/* CHECKSUM={C93B91C7D6862505D2C18CCA284AF854CCAFAA53} */
/* Daimler Truck AG */
/* All rights reserved */
/* Description: LIN Description file */
/* Network: THERMO_LIN2 */
/* Release: 2026-7a */
/* Engineer: Bianda, TP/XMS; W. Griebel EVOUL */
/* Creation Date: 2026-02-12 */
/* Status: RELEASED */
/* XDIS-Database: CVD-Database */

LIN_description_file;
LIN_protocol_version = "2.1";
LIN_language_version = "2.1";
LIN_speed = 19.200 kbps;

Channel_name = "THERMO_LIN2";

Nodes {
  Master : TIO_LIN2_Master, 5.000 ms, 0.200 ms;
  Slaves : CABP2, CPH2, ERC2, EXV2, FRVC10, FRVC19, FRVC2, FRVC21, FRVC25, FRVC26, FRVC3, FRVC4, P_T_SENSOR;
}

Signals {
  ASC_TIO_ERC2 : 2, 3, TIO_LIN2_Master, ERC2;
  ActPosnSave_Rq_TIO_FRVC10 : 1, 0, TIO_LIN2_Master, FRVC10;
  ActPosnSave_Rq_TIO_FRVC19 : 1, 0, TIO_LIN2_Master, FRVC19;
  ActPosnSave_Rq_TIO_FRVC2 : 1, 0, TIO_LIN2_Master, FRVC2;
  ActPosnSave_Rq_TIO_FRVC21 : 1, 0, TIO_LIN2_Master, FRVC21;
  ActPosnSave_Rq_TIO_FRVC25 : 1, 0, TIO_LIN2_Master, FRVC25;
  ActPosnSave_Rq_TIO_FRVC26 : 1, 0, TIO_LIN2_Master, FRVC26;
  ActPosnSave_Rq_TIO_FRVC3 : 1, 0, TIO_LIN2_Master, FRVC3;
  ActPosnSave_Rq_TIO_FRVC4 : 1, 0, TIO_LIN2_Master, FRVC4;
  ActlCurr_Cval_CABP2 : 8, 255, CABP2, TIO_LIN2_Master;
  AllPosnAdj_Stat_FRVC10 : 1, 0, FRVC10, TIO_LIN2_Master;
  AllPosnAdj_Stat_FRVC19 : 1, 0, FRVC19, TIO_LIN2_Master;
  AllPosnAdj_Stat_FRVC2 : 1, 0, FRVC2, TIO_LIN2_Master;
  AllPosnAdj_Stat_FRVC21 : 1, 0, FRVC21, TIO_LIN2_Master;
  AllPosnAdj_Stat_FRVC25 : 1, 0, FRVC25, TIO_LIN2_Master;
  AllPosnAdj_Stat_FRVC26 : 1, 0, FRVC26, TIO_LIN2_Master;
  AllPosnAdj_Stat_FRVC3 : 1, 0, FRVC3, TIO_LIN2_Master;
  AllPosnAdj_Stat_FRVC4 : 1, 0, FRVC4, TIO_LIN2_Master;
  BlockFlt_Stat_CABP2 : 2, 3, CABP2, TIO_LIN2_Master;
  CmprOn_Rq_TIO_ERC2 : 2, 3, TIO_LIN2_Master, ERC2;
  CmprOprtnV2_Stat_ERC2 : 3, 7, ERC2, TIO_LIN2_Master;
  CmprSpdTrgtV2_Rq_TIO_ERC2 : 8, 255, TIO_LIN2_Master, ERC2;
  CmprSpdV2_Cval_ERC2 : 8, 255, ERC2, TIO_LIN2_Master;
  ComFlt_ERC2 : 1, 0, ERC2, TIO_LIN2_Master;
  CoolntInTemp_Cval_CPH_BATT1 : 8, 255, CPH2, TIO_LIN2_Master;
  CoolntOutTemp_Cval_CPH_BATT1 : 8, 255, CPH2, TIO_LIN2_Master;
  CoolntPreHt_Stat_CPH_BATT1 : 4, 15, CPH2, TIO_LIN2_Master;
  CoolntTemp_Rq_TIO_CPH_BATT1 : 8, 255, TIO_LIN2_Master, CPH2;
  CptProtn_Stat_CPH_BATT1 : 2, 3, CPH2, TIO_LIN2_Master;
  Crash_Lin : 2, 3, TIO_LIN2_Master, ERC2;
  CurrLimFlt_ERC2 : 1, 0, ERC2, TIO_LIN2_Master;
  DCDCCnvrFai_Stat_CPH_BATT1 : 2, 3, CPH2, TIO_LIN2_Master;
  DIAG_Stat_Aliv_St_Cnt_ERC2 : 4, 0, ERC2, TIO_LIN2_Master;
  DIAG_Stat_Data1_ERC2 : 6, 0, ERC2, TIO_LIN2_Master;
  DIAG_Stat_Data2_ERC2 : 6, 0, ERC2, TIO_LIN2_Master;
  DIAG_Stat_Data3_ERC2 : 6, 0, ERC2, TIO_LIN2_Master;
  DIAG_Stat_Data4_ERC2 : 6, 0, ERC2, TIO_LIN2_Master;
  DIAG_Stat_Data5_ERC2 : 6, 0, ERC2, TIO_LIN2_Master;
  DIAG_Stat_Data6_ERC2 : 6, 0, ERC2, TIO_LIN2_Master;
  DIAG_Stat_Data7_ERC2 : 6, 0, ERC2, TIO_LIN2_Master;
  DIAG_Stat_Data8_ERC2 : 6, 0, ERC2, TIO_LIN2_Master;
  DIAG_Stat_Idx_Actl_ERC2 : 6, 0, ERC2, TIO_LIN2_Master;
  DIAG_Stat_Num_Max_ERC2 : 6, 0, ERC2, TIO_LIN2_Master;
  Dischrg_Rq_TIO_CPH_BATT1 : 1, 0, TIO_LIN2_Master, CPH2;
  Dischrg_Stat_CPH_BATT1 : 4, 15, CPH2, TIO_LIN2_Master;
  DryRun_Flt_Stat_CABP2 : 2, 3, CABP2, TIO_LIN2_Master;
  EXV2_Fault_Stat : 4, 15, EXV2, TIO_LIN2_Master;
  EXV2_OverTemp_Warn : 2, 3, EXV2, TIO_LIN2_Master;
  EXV2_Pos : 10, 1023, EXV2, TIO_LIN2_Master;
  EXV2_Run_Stat : 2, 3, EXV2, TIO_LIN2_Master;
  EXV2_SpdMd : 3, 7, EXV2, TIO_LIN2_Master;
  EXV2_Stall_Dtct_Stat : 2, 3, EXV2, TIO_LIN2_Master;
  EXV2_Version : 3, 7, EXV2, TIO_LIN2_Master;
  EXV2_Volt_Stat : 2, 3, EXV2, TIO_LIN2_Master;
  EXV2_curInit_Stat : 2, 3, EXV2, TIO_LIN2_Master;
  ElctrcFlt_Stat_CABP2 : 2, 3, CABP2, TIO_LIN2_Master;
  ElctrcTemp_Cval_CABP2 : 8, 255, CABP2, TIO_LIN2_Master;
  EltlErr_Stat_FRVC10 : 1, 0, FRVC10, TIO_LIN2_Master;
  EltlErr_Stat_FRVC19 : 1, 0, FRVC19, TIO_LIN2_Master;
  EltlErr_Stat_FRVC2 : 1, 0, FRVC2, TIO_LIN2_Master;
  EltlErr_Stat_FRVC21 : 1, 0, FRVC21, TIO_LIN2_Master;
  EltlErr_Stat_FRVC25 : 1, 0, FRVC25, TIO_LIN2_Master;
  EltlErr_Stat_FRVC26 : 1, 0, FRVC26, TIO_LIN2_Master;
  EltlErr_Stat_FRVC3 : 1, 0, FRVC3, TIO_LIN2_Master;
  EltlErr_Stat_FRVC4 : 1, 0, FRVC4, TIO_LIN2_Master;
  Err_Stat_FRVC10 : 4, 15, FRVC10, TIO_LIN2_Master;
  Err_Stat_FRVC19 : 4, 15, FRVC19, TIO_LIN2_Master;
  Err_Stat_FRVC2 : 4, 15, FRVC2, TIO_LIN2_Master;
  Err_Stat_FRVC21 : 4, 15, FRVC21, TIO_LIN2_Master;
  Err_Stat_FRVC25 : 4, 15, FRVC25, TIO_LIN2_Master;
  Err_Stat_FRVC26 : 4, 15, FRVC26, TIO_LIN2_Master;
  Err_Stat_FRVC3 : 4, 15, FRVC3, TIO_LIN2_Master;
  Err_Stat_FRVC4 : 4, 15, FRVC4, TIO_LIN2_Master;
  ExtPowerSupFlt_ERC2 : 1, 0, ERC2, TIO_LIN2_Master;
  GrpErr_Stat_FRVC10 : 1, 0, FRVC10, TIO_LIN2_Master;
  GrpErr_Stat_FRVC19 : 1, 0, FRVC19, TIO_LIN2_Master;
  GrpErr_Stat_FRVC2 : 1, 0, FRVC2, TIO_LIN2_Master;
  GrpErr_Stat_FRVC21 : 1, 0, FRVC21, TIO_LIN2_Master;
  GrpErr_Stat_FRVC25 : 1, 0, FRVC25, TIO_LIN2_Master;
  GrpErr_Stat_FRVC26 : 1, 0, FRVC26, TIO_LIN2_Master;
  GrpErr_Stat_FRVC3 : 1, 0, FRVC3, TIO_LIN2_Master;
  GrpErr_Stat_FRVC4 : 1, 0, FRVC4, TIO_LIN2_Master;
  HVAC_EXV2_Init_Dir : 2, 3, TIO_LIN2_Master, EXV2;
  HVAC_EXV2_Init_Rq : 3, 7, TIO_LIN2_Master, EXV2;
  HVAC_EXV2_Move_Enbl : 2, 3, TIO_LIN2_Master, EXV2;
  HVAC_EXV2_Set_Rq : 10, 1023, TIO_LIN2_Master, EXV2;
  HVAC_EXV2_SpdMd_Rq : 3, 7, TIO_LIN2_Master, EXV2;
  HVAC_EXV2_Stall_Dtct_Enbl : 2, 3, TIO_LIN2_Master, EXV2;
  HVAC_EXV2_Trq_Md_Rq : 3, 7, TIO_LIN2_Master, EXV2;
  HVCurr_Cval_CPH_BATT1 : 8, 255, CPH2, TIO_LIN2_Master;
  HVOutOfRngWarn_Stat_CPH_BATT1 : 2, 3, CPH2, TIO_LIN2_Master;
  HVVolt_Cval_CPH_BATT1 : 16, 65535, CPH2, TIO_LIN2_Master;
  HV_DCCurr_Cval_ERC2 : 8, 255, ERC2, TIO_LIN2_Master;
  HV_PhaseCurr_Cval_ERC2 : 7, 127, ERC2, TIO_LIN2_Master;
  HV_VoltLimFlt_ERC2 : 1, 0, ERC2, TIO_LIN2_Master;
  HV_Volt_Cval_ERC2 : 8, 255, ERC2, TIO_LIN2_Master;
  HiCurrFai_Stat_CPH_BATT1 : 2, 3, CPH2, TIO_LIN2_Master;
  HotSptFai_Stat_CPH_BATT1 : 2, 3, CPH2, TIO_LIN2_Master;
  HtEnbl_Rq_TIO_CPH_BATT1 : 1, 0, TIO_LIN2_Master, CPH2;
  IGBTDrvFai_Stat_CPH_BATT1 : 2, 3, CPH2, TIO_LIN2_Master;
  InfVarPosn_Cval_FRVC10 : 16, 65535, FRVC10, TIO_LIN2_Master;
  InfVarPosn_Cval_FRVC19 : 16, 65535, FRVC19, TIO_LIN2_Master;
  InfVarPosn_Cval_FRVC2 : 16, 65535, FRVC2, TIO_LIN2_Master;
  InfVarPosn_Cval_FRVC21 : 16, 65535, FRVC21, TIO_LIN2_Master;
  InfVarPosn_Cval_FRVC25 : 16, 65535, FRVC25, TIO_LIN2_Master;
  InfVarPosn_Cval_FRVC26 : 16, 65535, FRVC26, TIO_LIN2_Master;
  InfVarPosn_Cval_FRVC3 : 16, 65535, FRVC3, TIO_LIN2_Master;
  InfVarPosn_Cval_FRVC4 : 16, 65535, FRVC4, TIO_LIN2_Master;
  InfVarPosn_Rq_TIO_FRVC10 : 16, 65535, TIO_LIN2_Master, FRVC10;
  InfVarPosn_Rq_TIO_FRVC19 : 16, 65535, TIO_LIN2_Master, FRVC19;
  InfVarPosn_Rq_TIO_FRVC2 : 16, 65535, TIO_LIN2_Master, FRVC2;
  InfVarPosn_Rq_TIO_FRVC21 : 16, 65535, TIO_LIN2_Master, FRVC21;
  InfVarPosn_Rq_TIO_FRVC25 : 16, 65535, TIO_LIN2_Master, FRVC25;
  InfVarPosn_Rq_TIO_FRVC26 : 16, 65535, TIO_LIN2_Master, FRVC26;
  InfVarPosn_Rq_TIO_FRVC3 : 16, 65535, TIO_LIN2_Master, FRVC3;
  InfVarPosn_Rq_TIO_FRVC4 : 16, 65535, TIO_LIN2_Master, FRVC4;
  IntFai_Stat_CPH_BATT1 : 2, 3, CPH2, TIO_LIN2_Master;
  IntPowerSupFlt_ERC2 : 1, 0, ERC2, TIO_LIN2_Master;
  InvTemp_Cval_ERC2 : 8, 255, ERC2, TIO_LIN2_Master;
  LVOutOfRngWarn_Stat_CPH_BATT1 : 2, 3, CPH2, TIO_LIN2_Master;
  LoVolt_Cval_CABP2 : 8, 255, CABP2, TIO_LIN2_Master;
  MechBreakErr_Stat_FRVC10 : 1, 0, FRVC10, TIO_LIN2_Master;
  MechBreakErr_Stat_FRVC19 : 1, 0, FRVC19, TIO_LIN2_Master;
  MechBreakErr_Stat_FRVC2 : 1, 0, FRVC2, TIO_LIN2_Master;
  MechBreakErr_Stat_FRVC21 : 1, 0, FRVC21, TIO_LIN2_Master;
  MechBreakErr_Stat_FRVC25 : 1, 0, FRVC25, TIO_LIN2_Master;
  MechBreakErr_Stat_FRVC26 : 1, 0, FRVC26, TIO_LIN2_Master;
  MechBreakErr_Stat_FRVC3 : 1, 0, FRVC3, TIO_LIN2_Master;
  MechBreakErr_Stat_FRVC4 : 1, 0, FRVC4, TIO_LIN2_Master;
  Mon_Stat_CABP2 : 2, 3, CABP2, TIO_LIN2_Master;
  Move_Stat_FRVC10 : 4, 15, FRVC10, TIO_LIN2_Master;
  Move_Stat_FRVC19 : 4, 15, FRVC19, TIO_LIN2_Master;
  Move_Stat_FRVC2 : 4, 15, FRVC2, TIO_LIN2_Master;
  Move_Stat_FRVC21 : 4, 15, FRVC21, TIO_LIN2_Master;
  Move_Stat_FRVC25 : 4, 15, FRVC25, TIO_LIN2_Master;
  Move_Stat_FRVC26 : 4, 15, FRVC26, TIO_LIN2_Master;
  Move_Stat_FRVC3 : 4, 15, FRVC3, TIO_LIN2_Master;
  Move_Stat_FRVC4 : 4, 15, FRVC4, TIO_LIN2_Master;
  OverCurrFlt_Stat_CABP2 : 2, 3, CABP2, TIO_LIN2_Master;
  OverHeatWarn_Stat_CPH_BATT1 : 2, 3, CPH2, TIO_LIN2_Master;
  OverTempErr_Stat_FRVC10 : 1, 0, FRVC10, TIO_LIN2_Master;
  OverTempErr_Stat_FRVC19 : 1, 0, FRVC19, TIO_LIN2_Master;
  OverTempErr_Stat_FRVC2 : 1, 0, FRVC2, TIO_LIN2_Master;
  OverTempErr_Stat_FRVC21 : 1, 0, FRVC21, TIO_LIN2_Master;
  OverTempErr_Stat_FRVC25 : 1, 0, FRVC25, TIO_LIN2_Master;
  OverTempErr_Stat_FRVC26 : 1, 0, FRVC26, TIO_LIN2_Master;
  OverTempErr_Stat_FRVC3 : 1, 0, FRVC3, TIO_LIN2_Master;
  OverTempErr_Stat_FRVC4 : 1, 0, FRVC4, TIO_LIN2_Master;
  OverTempFlt_Stat_CABP2 : 2, 3, CABP2, TIO_LIN2_Master;
  OverTempWarn_Stat_FRVC10 : 1, 0, FRVC10, TIO_LIN2_Master;
  OverTempWarn_Stat_FRVC19 : 1, 0, FRVC19, TIO_LIN2_Master;
  OverTempWarn_Stat_FRVC2 : 1, 0, FRVC2, TIO_LIN2_Master;
  OverTempWarn_Stat_FRVC21 : 1, 0, FRVC21, TIO_LIN2_Master;
  OverTempWarn_Stat_FRVC25 : 1, 0, FRVC25, TIO_LIN2_Master;
  OverTempWarn_Stat_FRVC26 : 1, 0, FRVC26, TIO_LIN2_Master;
  OverTempWarn_Stat_FRVC3 : 1, 0, FRVC3, TIO_LIN2_Master;
  OverTempWarn_Stat_FRVC4 : 1, 0, FRVC4, TIO_LIN2_Master;
  OverVoltErr_Stat_FRVC10 : 1, 0, FRVC10, TIO_LIN2_Master;
  OverVoltErr_Stat_FRVC19 : 1, 0, FRVC19, TIO_LIN2_Master;
  OverVoltErr_Stat_FRVC2 : 1, 0, FRVC2, TIO_LIN2_Master;
  OverVoltErr_Stat_FRVC21 : 1, 0, FRVC21, TIO_LIN2_Master;
  OverVoltErr_Stat_FRVC25 : 1, 0, FRVC25, TIO_LIN2_Master;
  OverVoltErr_Stat_FRVC26 : 1, 0, FRVC26, TIO_LIN2_Master;
  OverVoltErr_Stat_FRVC3 : 1, 0, FRVC3, TIO_LIN2_Master;
  OverVoltErr_Stat_FRVC4 : 1, 0, FRVC4, TIO_LIN2_Master;
  PWM_Stat_CABP2 : 2, 3, CABP2, TIO_LIN2_Master;
  P_T_Sens2_ChkSum_Err : 1, 0, P_T_SENSOR, TIO_LIN2_Master;
  P_T_Sens2_CoolPress : 12, 4095, P_T_SENSOR, TIO_LIN2_Master;
  P_T_Sens2_CoolTemp : 12, 4095, P_T_SENSOR, TIO_LIN2_Master;
  P_T_Sens2_FailTest_Compl : 1, 0, P_T_SENSOR, TIO_LIN2_Master;
  P_T_Sens2_Global_Err : 1, 0, P_T_SENSOR, TIO_LIN2_Master;
  P_T_Sens2_IntTemp : 12, 4095, P_T_SENSOR, TIO_LIN2_Master;
  PerctSpd_Cval_CABP2 : 8, 255, CABP2, TIO_LIN2_Master;
  Perct_Cval_CPH_BATT1 : 8, 255, CPH2, TIO_LIN2_Master;
  Perct_Rq_TIO_CPH_BATT1 : 8, 255, TIO_LIN2_Master, CPH2;
  PosSnaErr_Stat_FRVC10 : 1, 0, FRVC10, TIO_LIN2_Master;
  PosSnaErr_Stat_FRVC19 : 1, 0, FRVC19, TIO_LIN2_Master;
  PosSnaErr_Stat_FRVC2 : 1, 0, FRVC2, TIO_LIN2_Master;
  PosSnaErr_Stat_FRVC21 : 1, 0, FRVC21, TIO_LIN2_Master;
  PosSnaErr_Stat_FRVC25 : 1, 0, FRVC25, TIO_LIN2_Master;
  PosSnaErr_Stat_FRVC26 : 1, 0, FRVC26, TIO_LIN2_Master;
  PosSnaErr_Stat_FRVC3 : 1, 0, FRVC3, TIO_LIN2_Master;
  PosSnaErr_Stat_FRVC4 : 1, 0, FRVC4, TIO_LIN2_Master;
  PostRunMode_CABP2 : 3, 0, CABP2, TIO_LIN2_Master;
  PowerCons_Cval_ERC2 : 8, 255, ERC2, TIO_LIN2_Master;
  RefRunEnbl_Rq_TIO_FRVC10 : 2, 3, TIO_LIN2_Master, FRVC10;
  RefRunEnbl_Rq_TIO_FRVC19 : 2, 3, TIO_LIN2_Master, FRVC19;
  RefRunEnbl_Rq_TIO_FRVC2 : 2, 3, TIO_LIN2_Master, FRVC2;
  RefRunEnbl_Rq_TIO_FRVC21 : 2, 3, TIO_LIN2_Master, FRVC21;
  RefRunEnbl_Rq_TIO_FRVC25 : 2, 3, TIO_LIN2_Master, FRVC25;
  RefRunEnbl_Rq_TIO_FRVC26 : 2, 3, TIO_LIN2_Master, FRVC26;
  RefRunEnbl_Rq_TIO_FRVC3 : 2, 3, TIO_LIN2_Master, FRVC3;
  RefRunEnbl_Rq_TIO_FRVC4 : 2, 3, TIO_LIN2_Master, FRVC4;
  RefRunErr_Stat_FRVC10 : 1, 0, FRVC10, TIO_LIN2_Master;
  RefRunErr_Stat_FRVC19 : 1, 0, FRVC19, TIO_LIN2_Master;
  RefRunErr_Stat_FRVC2 : 1, 0, FRVC2, TIO_LIN2_Master;
  RefRunErr_Stat_FRVC21 : 1, 0, FRVC21, TIO_LIN2_Master;
  RefRunErr_Stat_FRVC25 : 1, 0, FRVC25, TIO_LIN2_Master;
  RefRunErr_Stat_FRVC26 : 1, 0, FRVC26, TIO_LIN2_Master;
  RefRunErr_Stat_FRVC3 : 1, 0, FRVC3, TIO_LIN2_Master;
  RefRunErr_Stat_FRVC4 : 1, 0, FRVC4, TIO_LIN2_Master;
  RefRun_Stat_FRVC10 : 1, 0, FRVC10, TIO_LIN2_Master;
  RefRun_Stat_FRVC19 : 1, 0, FRVC19, TIO_LIN2_Master;
  RefRun_Stat_FRVC2 : 1, 0, FRVC2, TIO_LIN2_Master;
  RefRun_Stat_FRVC21 : 1, 0, FRVC21, TIO_LIN2_Master;
  RefRun_Stat_FRVC25 : 1, 0, FRVC25, TIO_LIN2_Master;
  RefRun_Stat_FRVC26 : 1, 0, FRVC26, TIO_LIN2_Master;
  RefRun_Stat_FRVC3 : 1, 0, FRVC3, TIO_LIN2_Master;
  RefRun_Stat_FRVC4 : 1, 0, FRVC4, TIO_LIN2_Master;
  RsErr_Cval_CABP2 : 1, 0, CABP2, TIO_LIN2_Master;
  RsErr_ERC2 : 1, 0, ERC2, TIO_LIN2_Master;
  RsErr_EXV2 : 1, 0, EXV2, TIO_LIN2_Master;
  RsErr_FRVC10 : 1, 0, FRVC10, TIO_LIN2_Master;
  RsErr_FRVC19 : 1, 0, FRVC19, TIO_LIN2_Master;
  RsErr_FRVC2 : 1, 0, FRVC2, TIO_LIN2_Master;
  RsErr_FRVC21 : 1, 0, FRVC21, TIO_LIN2_Master;
  RsErr_FRVC25 : 1, 0, FRVC25, TIO_LIN2_Master;
  RsErr_FRVC26 : 1, 0, FRVC26, TIO_LIN2_Master;
  RsErr_FRVC3 : 1, 0, FRVC3, TIO_LIN2_Master;
  RsErr_FRVC4 : 1, 0, FRVC4, TIO_LIN2_Master;
  RsErr_P_T_SENSOR2 : 1, 0, P_T_SENSOR, TIO_LIN2_Master;
  RsErr_Stat_CPH_BATT1 : 1, 0, CPH2, TIO_LIN2_Master;
  Rst_Rq_TIO_ERC2 : 2, 3, TIO_LIN2_Master, ERC2;
  SemiConductSwRq_TIO_CPH_BATT1 : 2, 3, TIO_LIN2_Master, CPH2;
  SemiConductSwRq_TIO_ERC2 : 2, 3, TIO_LIN2_Master, ERC2;
  SemiConductSw_Stat_CPH_BATT1 : 2, 3, CPH2, TIO_LIN2_Master;
  SemiConductSw_Stat_ERC2 : 2, 3, ERC2, TIO_LIN2_Master;
  ShtdnExcTrqStallFlt_ERC2 : 1, 0, ERC2, TIO_LIN2_Master;
  ShtdnSensFlt_ERC2 : 1, 0, ERC2, TIO_LIN2_Master;
  ShtdnShrtCrcFlt_ERC2 : 1, 0, ERC2, TIO_LIN2_Master;
  SpVoltFlt_Stat_CABP2 : 2, 3, CABP2, TIO_LIN2_Master;
  StepPosn_Stat_FRVC10 : 4, 15, FRVC10, TIO_LIN2_Master;
  StepPosn_Stat_FRVC19 : 4, 15, FRVC19, TIO_LIN2_Master;
  StepPosn_Stat_FRVC2 : 4, 15, FRVC2, TIO_LIN2_Master;
  StepPosn_Stat_FRVC21 : 4, 15, FRVC21, TIO_LIN2_Master;
  StepPosn_Stat_FRVC25 : 4, 15, FRVC25, TIO_LIN2_Master;
  StepPosn_Stat_FRVC26 : 4, 15, FRVC26, TIO_LIN2_Master;
  StepPosn_Stat_FRVC3 : 4, 15, FRVC3, TIO_LIN2_Master;
  StepPosn_Stat_FRVC4 : 4, 15, FRVC4, TIO_LIN2_Master;
  TempExcFlt_ERC2 : 1, 0, ERC2, TIO_LIN2_Master;
  TempLimBoostFlt_ERC2 : 1, 0, ERC2, TIO_LIN2_Master;
  TempSensFai_Stat_CPH_BATT1 : 2, 3, CPH2, TIO_LIN2_Master;
  TrgtPerctSpd_Cval_CABP2 : 8, 255, CABP2, TIO_LIN2_Master;
  TrgtPerctSpd_Rq_CABP2 : 8, 255, TIO_LIN2_Master, CABP2;
  TrqExcFlt_ERC2 : 1, 0, ERC2, TIO_LIN2_Master;
  UndrVoltErr_Stat_FRVC10 : 1, 0, FRVC10, TIO_LIN2_Master;
  UndrVoltErr_Stat_FRVC19 : 1, 0, FRVC19, TIO_LIN2_Master;
  UndrVoltErr_Stat_FRVC2 : 1, 0, FRVC2, TIO_LIN2_Master;
  UndrVoltErr_Stat_FRVC21 : 1, 0, FRVC21, TIO_LIN2_Master;
  UndrVoltErr_Stat_FRVC25 : 1, 0, FRVC25, TIO_LIN2_Master;
  UndrVoltErr_Stat_FRVC26 : 1, 0, FRVC26, TIO_LIN2_Master;
  UndrVoltErr_Stat_FRVC3 : 1, 0, FRVC3, TIO_LIN2_Master;
  UndrVoltErr_Stat_FRVC4 : 1, 0, FRVC4, TIO_LIN2_Master;
  UnexpBlkErr_Stat_FRVC10 : 1, 0, FRVC10, TIO_LIN2_Master;
  UnexpBlkErr_Stat_FRVC19 : 1, 0, FRVC19, TIO_LIN2_Master;
  UnexpBlkErr_Stat_FRVC2 : 1, 0, FRVC2, TIO_LIN2_Master;
  UnexpBlkErr_Stat_FRVC21 : 1, 0, FRVC21, TIO_LIN2_Master;
  UnexpBlkErr_Stat_FRVC25 : 1, 0, FRVC25, TIO_LIN2_Master;
  UnexpBlkErr_Stat_FRVC26 : 1, 0, FRVC26, TIO_LIN2_Master;
  UnexpBlkErr_Stat_FRVC3 : 1, 0, FRVC3, TIO_LIN2_Master;
  UnexpBlkErr_Stat_FRVC4 : 1, 0, FRVC4, TIO_LIN2_Master;
  WakeUp_Stat_FRVC10 : 2, 3, FRVC10, TIO_LIN2_Master;
  WakeUp_Stat_FRVC19 : 2, 3, FRVC19, TIO_LIN2_Master;
  WakeUp_Stat_FRVC2 : 2, 3, FRVC2, TIO_LIN2_Master;
  WakeUp_Stat_FRVC21 : 2, 3, FRVC21, TIO_LIN2_Master;
  WakeUp_Stat_FRVC25 : 2, 3, FRVC25, TIO_LIN2_Master;
  WakeUp_Stat_FRVC26 : 2, 3, FRVC26, TIO_LIN2_Master;
  WakeUp_Stat_FRVC3 : 2, 3, FRVC3, TIO_LIN2_Master;
  WakeUp_Stat_FRVC4 : 2, 3, FRVC4, TIO_LIN2_Master;
  WakeupStat_EXV2 : 2, 3, EXV2, TIO_LIN2_Master;
  Wakeup_Stat_CABP2 : 2, 3, CABP2, TIO_LIN2_Master;
  Wakeup_Stat_ERC2 : 2, 3, ERC2, TIO_LIN2_Master;
}

Frames {
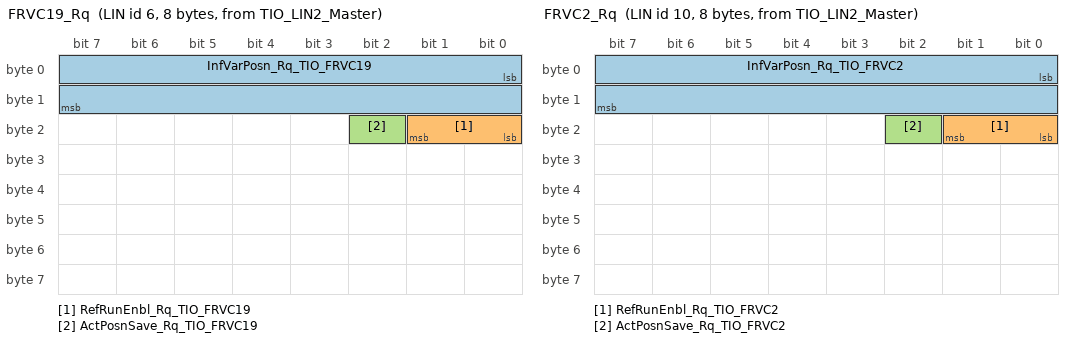
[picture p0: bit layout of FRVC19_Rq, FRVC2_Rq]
  FRVC19_Rq : 6, TIO_LIN2_Master, 8 {
    InfVarPosn_Rq_TIO_FRVC19, 0;
    RefRunEnbl_Rq_TIO_FRVC19, 16;
    ActPosnSave_Rq_TIO_FRVC19, 18;
  }
  ERC2_Frm2 : 7, ERC2, 8 {
    SemiConductSw_Stat_ERC2, 0;
  }
  FRVC19_Cval : 8, FRVC19, 8 {
    StepPosn_Stat_FRVC19, 0;
    Move_Stat_FRVC19, 4;
    Err_Stat_FRVC19, 8;
    EltlErr_Stat_FRVC19, 12;
    UndrVoltErr_Stat_FRVC19, 13;
    OverVoltErr_Stat_FRVC19, 14;
    OverTempErr_Stat_FRVC19, 15;
    MechBreakErr_Stat_FRVC19, 16;
    UnexpBlkErr_Stat_FRVC19, 17;
    RefRunErr_Stat_FRVC19, 18;
    GrpErr_Stat_FRVC19, 19;
    PosSnaErr_Stat_FRVC19, 20;
    RefRun_Stat_FRVC19, 21;
    AllPosnAdj_Stat_FRVC19, 22;
    OverTempWarn_Stat_FRVC19, 23;
    InfVarPosn_Cval_FRVC19, 24;
    RsErr_FRVC19, 61;
    WakeUp_Stat_FRVC19, 62;
  }
  FRVC2_Rq : 10, TIO_LIN2_Master, 8 {
    InfVarPosn_Rq_TIO_FRVC2, 0;
    RefRunEnbl_Rq_TIO_FRVC2, 16;
    ActPosnSave_Rq_TIO_FRVC2, 18;
  }
  FRVC2_Cval : 11, FRVC2, 8 {
    StepPosn_Stat_FRVC2, 0;
    Move_Stat_FRVC2, 4;
    Err_Stat_FRVC2, 8;
    EltlErr_Stat_FRVC2, 12;
    UndrVoltErr_Stat_FRVC2, 13;
    OverVoltErr_Stat_FRVC2, 14;
    OverTempErr_Stat_FRVC2, 15;
    MechBreakErr_Stat_FRVC2, 16;
    UnexpBlkErr_Stat_FRVC2, 17;
    RefRunErr_Stat_FRVC2, 18;
    GrpErr_Stat_FRVC2, 19;
    PosSnaErr_Stat_FRVC2, 20;
    RefRun_Stat_FRVC2, 21;
    AllPosnAdj_Stat_FRVC2, 22;
    OverTempWarn_Stat_FRVC2, 23;
    InfVarPosn_Cval_FRVC2, 24;
    RsErr_FRVC2, 61;
    WakeUp_Stat_FRVC2, 62;
  }
  FRVC21_Cval : 13, FRVC21, 8 {
    StepPosn_Stat_FRVC21, 0;
    Move_Stat_FRVC21, 4;
    Err_Stat_FRVC21, 8;
    EltlErr_Stat_FRVC21, 12;
    UndrVoltErr_Stat_FRVC21, 13;
    OverVoltErr_Stat_FRVC21, 14;
    OverTempErr_Stat_FRVC21, 15;
    MechBreakErr_Stat_FRVC21, 16;
    UnexpBlkErr_Stat_FRVC21, 17;
    RefRunErr_Stat_FRVC21, 18;
    GrpErr_Stat_FRVC21, 19;
    PosSnaErr_Stat_FRVC21, 20;
    RefRun_Stat_FRVC21, 21;
    AllPosnAdj_Stat_FRVC21, 22;
    OverTempWarn_Stat_FRVC21, 23;
    InfVarPosn_Cval_FRVC21, 24;
    RsErr_FRVC21, 61;
    WakeUp_Stat_FRVC21, 62;
  }
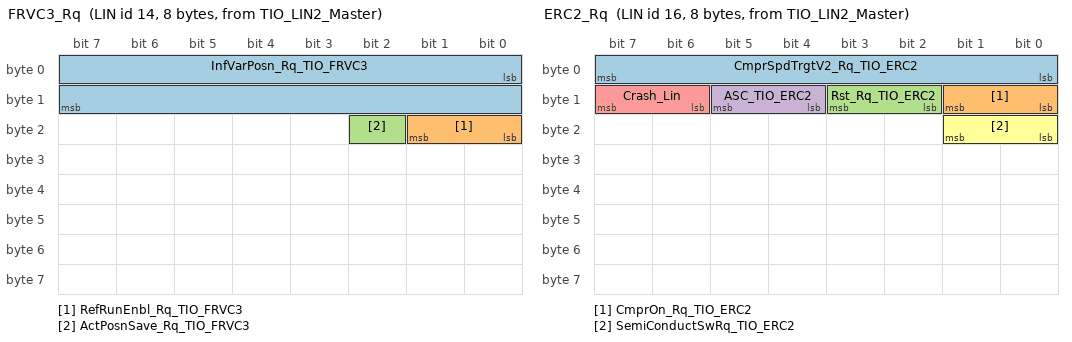
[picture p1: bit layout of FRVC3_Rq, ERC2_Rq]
  FRVC3_Rq : 14, TIO_LIN2_Master, 8 {
    InfVarPosn_Rq_TIO_FRVC3, 0;
    RefRunEnbl_Rq_TIO_FRVC3, 16;
    ActPosnSave_Rq_TIO_FRVC3, 18;
  }
  FRVC3_Cval : 15, FRVC3, 8 {
    StepPosn_Stat_FRVC3, 0;
    Move_Stat_FRVC3, 4;
    Err_Stat_FRVC3, 8;
    EltlErr_Stat_FRVC3, 12;
    UndrVoltErr_Stat_FRVC3, 13;
    OverVoltErr_Stat_FRVC3, 14;
    OverTempErr_Stat_FRVC3, 15;
    MechBreakErr_Stat_FRVC3, 16;
    UnexpBlkErr_Stat_FRVC3, 17;
    RefRunErr_Stat_FRVC3, 18;
    GrpErr_Stat_FRVC3, 19;
    PosSnaErr_Stat_FRVC3, 20;
    RefRun_Stat_FRVC3, 21;
    AllPosnAdj_Stat_FRVC3, 22;
    OverTempWarn_Stat_FRVC3, 23;
    InfVarPosn_Cval_FRVC3, 24;
    RsErr_FRVC3, 61;
    WakeUp_Stat_FRVC3, 62;
  }
  ERC2_Rq : 16, TIO_LIN2_Master, 8 {
    CmprSpdTrgtV2_Rq_TIO_ERC2, 0;
    CmprOn_Rq_TIO_ERC2, 8;
    Rst_Rq_TIO_ERC2, 10;
    ASC_TIO_ERC2, 12;
    Crash_Lin, 14;
    SemiConductSwRq_TIO_ERC2, 16;
  }
  FRVC4_Cval : 17, FRVC4, 8 {
    StepPosn_Stat_FRVC4, 0;
    Move_Stat_FRVC4, 4;
    Err_Stat_FRVC4, 8;
    EltlErr_Stat_FRVC4, 12;
    UndrVoltErr_Stat_FRVC4, 13;
    OverVoltErr_Stat_FRVC4, 14;
    OverTempErr_Stat_FRVC4, 15;
    MechBreakErr_Stat_FRVC4, 16;
    UnexpBlkErr_Stat_FRVC4, 17;
    RefRunErr_Stat_FRVC4, 18;
    GrpErr_Stat_FRVC4, 19;
    PosSnaErr_Stat_FRVC4, 20;
    RefRun_Stat_FRVC4, 21;
    AllPosnAdj_Stat_FRVC4, 22;
    OverTempWarn_Stat_FRVC4, 23;
    InfVarPosn_Cval_FRVC4, 24;
    RsErr_FRVC4, 61;
    WakeUp_Stat_FRVC4, 62;
  }
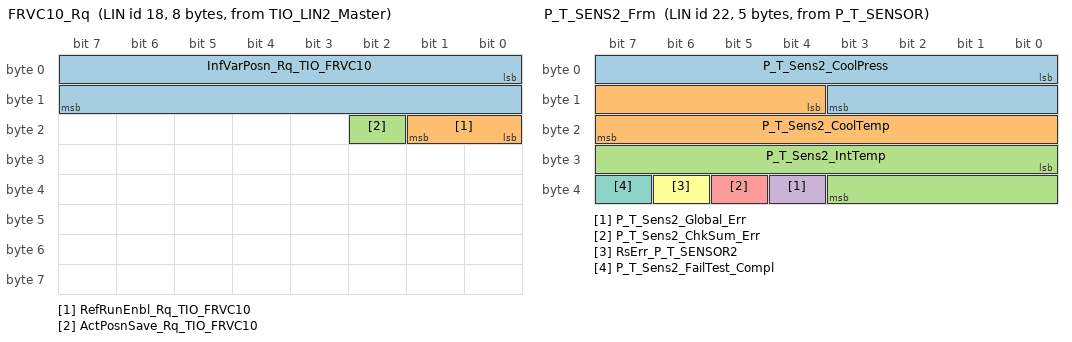
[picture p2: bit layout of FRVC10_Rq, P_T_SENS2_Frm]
  FRVC10_Rq : 18, TIO_LIN2_Master, 8 {
    InfVarPosn_Rq_TIO_FRVC10, 0;
    RefRunEnbl_Rq_TIO_FRVC10, 16;
    ActPosnSave_Rq_TIO_FRVC10, 18;
  }
  FRVC10_Cval : 19, FRVC10, 8 {
    StepPosn_Stat_FRVC10, 0;
    Move_Stat_FRVC10, 4;
    Err_Stat_FRVC10, 8;
    EltlErr_Stat_FRVC10, 12;
    UndrVoltErr_Stat_FRVC10, 13;
    OverVoltErr_Stat_FRVC10, 14;
    OverTempErr_Stat_FRVC10, 15;
    MechBreakErr_Stat_FRVC10, 16;
    UnexpBlkErr_Stat_FRVC10, 17;
    RefRunErr_Stat_FRVC10, 18;
    GrpErr_Stat_FRVC10, 19;
    PosSnaErr_Stat_FRVC10, 20;
    RefRun_Stat_FRVC10, 21;
    AllPosnAdj_Stat_FRVC10, 22;
    OverTempWarn_Stat_FRVC10, 23;
    InfVarPosn_Cval_FRVC10, 24;
    RsErr_FRVC10, 61;
    WakeUp_Stat_FRVC10, 62;
  }
  P_T_SENS2_Frm : 22, P_T_SENSOR, 5 {
    P_T_Sens2_CoolPress, 0;
    P_T_Sens2_CoolTemp, 12;
    P_T_Sens2_IntTemp, 24;
    P_T_Sens2_Global_Err, 36;
    P_T_Sens2_ChkSum_Err, 37;
    RsErr_P_T_SENSOR2, 38;
    P_T_Sens2_FailTest_Compl, 39;
  }
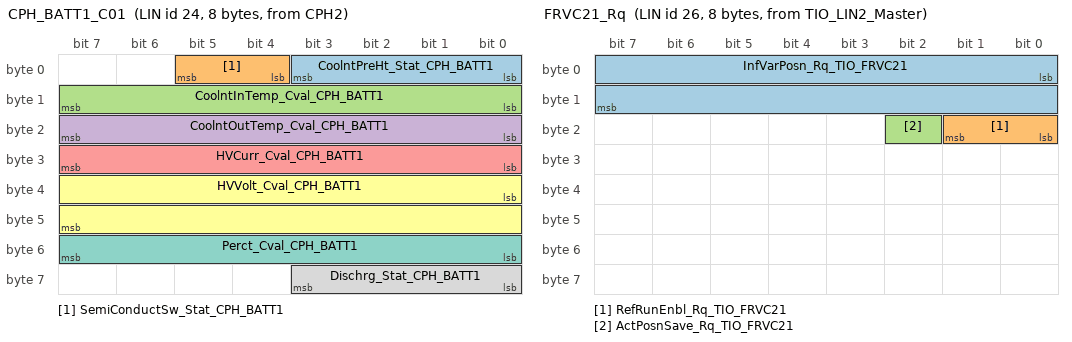
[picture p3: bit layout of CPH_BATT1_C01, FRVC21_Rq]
  CPH_BATT1_C01 : 24, CPH2, 8 {
    CoolntPreHt_Stat_CPH_BATT1, 0;
    SemiConductSw_Stat_CPH_BATT1, 4;
    CoolntInTemp_Cval_CPH_BATT1, 8;
    CoolntOutTemp_Cval_CPH_BATT1, 16;
    HVCurr_Cval_CPH_BATT1, 24;
    HVVolt_Cval_CPH_BATT1, 32;
    Perct_Cval_CPH_BATT1, 48;
    Dischrg_Stat_CPH_BATT1, 56;
  }
  FRVC21_Rq : 26, TIO_LIN2_Master, 8 {
    InfVarPosn_Rq_TIO_FRVC21, 0;
    RefRunEnbl_Rq_TIO_FRVC21, 16;
    ActPosnSave_Rq_TIO_FRVC21, 18;
  }
  ERC2_Frm1 : 31, ERC2, 8 {
    CmprSpdV2_Cval_ERC2, 0;
    PowerCons_Cval_ERC2, 8;
    HV_DCCurr_Cval_ERC2, 16;
    HV_Volt_Cval_ERC2, 24;
    InvTemp_Cval_ERC2, 32;
    HV_PhaseCurr_Cval_ERC2, 40;
    RsErr_ERC2, 47;
    TempLimBoostFlt_ERC2, 48;
    CurrLimFlt_ERC2, 49;
    HV_VoltLimFlt_ERC2, 50;
    TempExcFlt_ERC2, 51;
    TrqExcFlt_ERC2, 52;
    ComFlt_ERC2, 53;
    ExtPowerSupFlt_ERC2, 54;
    IntPowerSupFlt_ERC2, 55;
    ShtdnSensFlt_ERC2, 56;
    ShtdnShrtCrcFlt_ERC2, 57;
    ShtdnExcTrqStallFlt_ERC2, 58;
    CmprOprtnV2_Stat_ERC2, 59;
    Wakeup_Stat_ERC2, 62;
  }
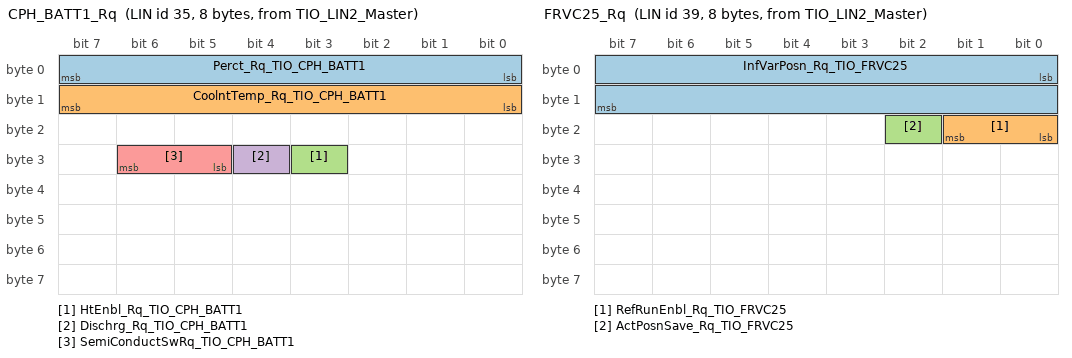
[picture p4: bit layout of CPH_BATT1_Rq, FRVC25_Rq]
  CPH_BATT1_Rq : 35, TIO_LIN2_Master, 8 {
    Perct_Rq_TIO_CPH_BATT1, 0;
    CoolntTemp_Rq_TIO_CPH_BATT1, 8;
    HtEnbl_Rq_TIO_CPH_BATT1, 27;
    Dischrg_Rq_TIO_CPH_BATT1, 28;
    SemiConductSwRq_TIO_CPH_BATT1, 29;
  }
  FRVC25_Cval : 38, FRVC25, 8 {
    StepPosn_Stat_FRVC25, 0;
    Move_Stat_FRVC25, 4;
    Err_Stat_FRVC25, 8;
    EltlErr_Stat_FRVC25, 12;
    UndrVoltErr_Stat_FRVC25, 13;
    OverVoltErr_Stat_FRVC25, 14;
    OverTempErr_Stat_FRVC25, 15;
    MechBreakErr_Stat_FRVC25, 16;
    UnexpBlkErr_Stat_FRVC25, 17;
    RefRunErr_Stat_FRVC25, 18;
    GrpErr_Stat_FRVC25, 19;
    PosSnaErr_Stat_FRVC25, 20;
    RefRun_Stat_FRVC25, 21;
    AllPosnAdj_Stat_FRVC25, 22;
    OverTempWarn_Stat_FRVC25, 23;
    InfVarPosn_Cval_FRVC25, 24;
    RsErr_FRVC25, 61;
    WakeUp_Stat_FRVC25, 62;
  }
  FRVC25_Rq : 39, TIO_LIN2_Master, 8 {
    InfVarPosn_Rq_TIO_FRVC25, 0;
    RefRunEnbl_Rq_TIO_FRVC25, 16;
    ActPosnSave_Rq_TIO_FRVC25, 18;
  }
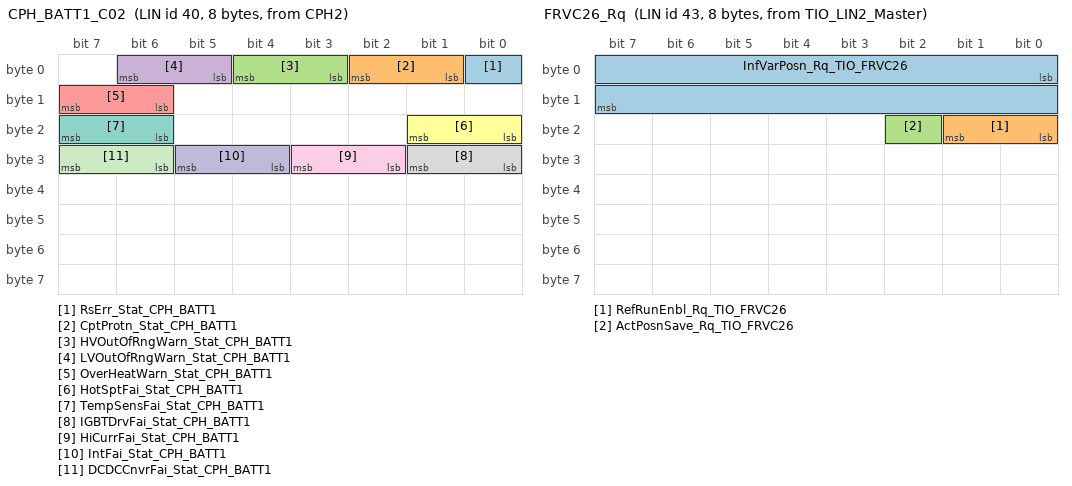
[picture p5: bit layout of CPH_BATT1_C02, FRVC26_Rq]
  CPH_BATT1_C02 : 40, CPH2, 8 {
    RsErr_Stat_CPH_BATT1, 0;
    CptProtn_Stat_CPH_BATT1, 1;
    HVOutOfRngWarn_Stat_CPH_BATT1, 3;
    LVOutOfRngWarn_Stat_CPH_BATT1, 5;
    OverHeatWarn_Stat_CPH_BATT1, 14;
    HotSptFai_Stat_CPH_BATT1, 16;
    TempSensFai_Stat_CPH_BATT1, 22;
    IGBTDrvFai_Stat_CPH_BATT1, 24;
    HiCurrFai_Stat_CPH_BATT1, 26;
    IntFai_Stat_CPH_BATT1, 28;
    DCDCCnvrFai_Stat_CPH_BATT1, 30;
  }
  FRVC26_Cval : 42, FRVC26, 8 {
    StepPosn_Stat_FRVC26, 0;
    Move_Stat_FRVC26, 4;
    Err_Stat_FRVC26, 8;
    EltlErr_Stat_FRVC26, 12;
    UndrVoltErr_Stat_FRVC26, 13;
    OverVoltErr_Stat_FRVC26, 14;
    OverTempErr_Stat_FRVC26, 15;
    MechBreakErr_Stat_FRVC26, 16;
    UnexpBlkErr_Stat_FRVC26, 17;
    RefRunErr_Stat_FRVC26, 18;
    GrpErr_Stat_FRVC26, 19;
    PosSnaErr_Stat_FRVC26, 20;
    RefRun_Stat_FRVC26, 21;
    AllPosnAdj_Stat_FRVC26, 22;
    OverTempWarn_Stat_FRVC26, 23;
    InfVarPosn_Cval_FRVC26, 24;
    RsErr_FRVC26, 61;
    WakeUp_Stat_FRVC26, 62;
  }
  FRVC26_Rq : 43, TIO_LIN2_Master, 8 {
    InfVarPosn_Rq_TIO_FRVC26, 0;
    RefRunEnbl_Rq_TIO_FRVC26, 16;
    ActPosnSave_Rq_TIO_FRVC26, 18;
  }
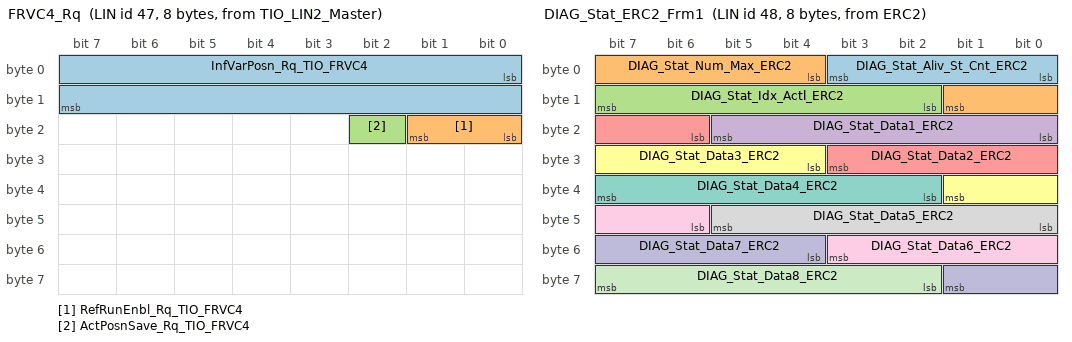
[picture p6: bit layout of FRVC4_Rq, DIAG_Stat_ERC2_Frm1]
  FRVC4_Rq : 47, TIO_LIN2_Master, 8 {
    InfVarPosn_Rq_TIO_FRVC4, 0;
    RefRunEnbl_Rq_TIO_FRVC4, 16;
    ActPosnSave_Rq_TIO_FRVC4, 18;
  }
  DIAG_Stat_ERC2_Frm1 : 48, ERC2, 8 {
    DIAG_Stat_Aliv_St_Cnt_ERC2, 0;
    DIAG_Stat_Num_Max_ERC2, 4;
    DIAG_Stat_Idx_Actl_ERC2, 10;
    DIAG_Stat_Data1_ERC2, 16;
    DIAG_Stat_Data2_ERC2, 22;
    DIAG_Stat_Data3_ERC2, 28;
    DIAG_Stat_Data4_ERC2, 34;
    DIAG_Stat_Data5_ERC2, 40;
    DIAG_Stat_Data6_ERC2, 46;
    DIAG_Stat_Data7_ERC2, 52;
    DIAG_Stat_Data8_ERC2, 58;
  }
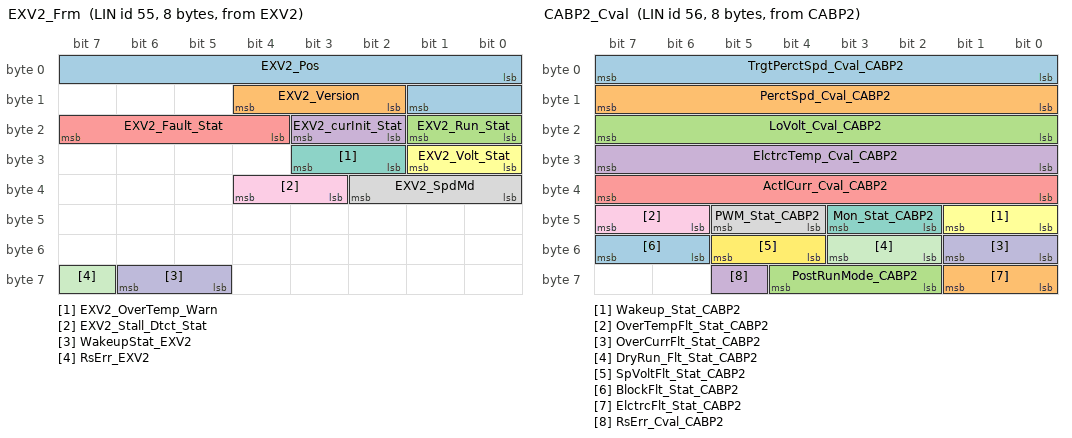
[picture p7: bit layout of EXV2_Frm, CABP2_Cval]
  EXV2_Frm : 55, EXV2, 8 {
    EXV2_Pos, 0;
    EXV2_Version, 10;
    EXV2_Run_Stat, 16;
    EXV2_curInit_Stat, 18;
    EXV2_Fault_Stat, 20;
    EXV2_Volt_Stat, 24;
    EXV2_OverTemp_Warn, 26;
    EXV2_SpdMd, 32;
    EXV2_Stall_Dtct_Stat, 35;
    WakeupStat_EXV2, 61;
    RsErr_EXV2, 63;
  }
  CABP2_Cval : 56, CABP2, 8 {
    TrgtPerctSpd_Cval_CABP2, 0;
    PerctSpd_Cval_CABP2, 8;
    LoVolt_Cval_CABP2, 16;
    ElctrcTemp_Cval_CABP2, 24;
    ActlCurr_Cval_CABP2, 32;
    Wakeup_Stat_CABP2, 40;
    Mon_Stat_CABP2, 42;
    PWM_Stat_CABP2, 44;
    OverTempFlt_Stat_CABP2, 46;
    OverCurrFlt_Stat_CABP2, 48;
    DryRun_Flt_Stat_CABP2, 50;
    SpVoltFlt_Stat_CABP2, 52;
    BlockFlt_Stat_CABP2, 54;
    ElctrcFlt_Stat_CABP2, 56;
    PostRunMode_CABP2, 58;
    RsErr_Cval_CABP2, 61;
  }
  CABP2_Rq : 57, TIO_LIN2_Master, 8 {
    TrgtPerctSpd_Rq_CABP2, 0;
  }
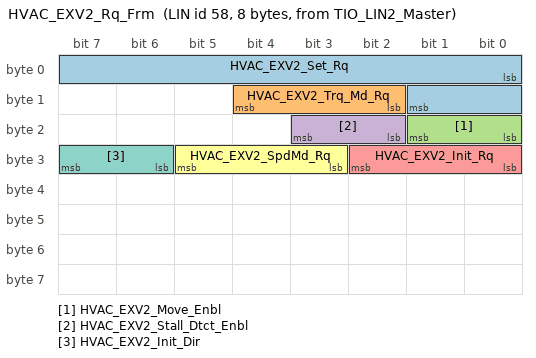
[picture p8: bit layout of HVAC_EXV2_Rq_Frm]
  HVAC_EXV2_Rq_Frm : 58, TIO_LIN2_Master, 8 {
    HVAC_EXV2_Set_Rq, 0;
    HVAC_EXV2_Trq_Md_Rq, 10;
    HVAC_EXV2_Move_Enbl, 16;
    HVAC_EXV2_Stall_Dtct_Enbl, 18;
    HVAC_EXV2_Init_Rq, 24;
    HVAC_EXV2_SpdMd_Rq, 27;
    HVAC_EXV2_Init_Dir, 30;
  }
}

Node_attributes {
  CABP2 {
    LIN_protocol = "2.1";
    configured_NAD = 0x0A;
    initial_NAD = 0x0A;
    product_id = 0x0000, 0x0074, 0x03;
    response_error = RsErr_Cval_CABP2;
    P2_min = 50 ms;
    ST_min = 0 ms;
    N_As_timeout = 1000 ms;
    N_Cr_timeout = 1000 ms;
    configurable_frames {
      CABP2_Cval;
      CABP2_Rq;
    }
  }
  CPH2 {
    LIN_protocol = "2.1";
    configured_NAD = 0x4F;
    initial_NAD = 0x4F;
    product_id = 0x0136, 0x0074, 0x03;
    response_error = RsErr_Stat_CPH_BATT1;
    P2_min = 50 ms;
    ST_min = 0 ms;
    N_As_timeout = 1000 ms;
    N_Cr_timeout = 1000 ms;
    configurable_frames {
      CPH_BATT1_Rq;
      CPH_BATT1_C02;
      CPH_BATT1_C01;
    }
  }
  ERC2 {
    LIN_protocol = "2.1";
    configured_NAD = 0x01;
    initial_NAD = 0x01;
    product_id = 0x0136, 0x0074, 0x03;
    response_error = RsErr_ERC2;
    P2_min = 50 ms;
    ST_min = 0 ms;
    N_As_timeout = 1000 ms;
    N_Cr_timeout = 1000 ms;
    configurable_frames {
      ERC2_Rq;
      DIAG_Stat_ERC2_Frm1;
      ERC2_Frm1;
      ERC2_Frm2;
    }
  }
  EXV2 {
    LIN_protocol = "2.1";
    configured_NAD = 0x05;
    initial_NAD = 0x05;
    product_id = 0x0124, 0x0001, 0x00;
    response_error = RsErr_EXV2;
    P2_min = 50 ms;
    ST_min = 0 ms;
    configurable_frames {
      EXV2_Frm;
      HVAC_EXV2_Rq_Frm;
    }
  }
  FRVC10 {
    LIN_protocol = "2.1";
    configured_NAD = 0x07;
    initial_NAD = 0x07;
    product_id = 0x0076, 0x1267, 0x00;
    response_error = RsErr_FRVC10;
    P2_min = 50 ms;
    ST_min = 0 ms;
    N_As_timeout = 1000 ms;
    N_Cr_timeout = 1000 ms;
    configurable_frames {
      FRVC10_Rq;
      FRVC10_Cval;
    }
  }
  FRVC19 {
    LIN_protocol = "2.1";
    configured_NAD = 0x09;
    initial_NAD = 0x09;
    product_id = 0x0076, 0x0000, 0x00;
    response_error = RsErr_FRVC19;
    P2_min = 50 ms;
    ST_min = 0 ms;
    N_As_timeout = 1000 ms;
    N_Cr_timeout = 1000 ms;
    configurable_frames {
      FRVC19_Cval;
      FRVC19_Rq;
    }
  }
  FRVC2 {
    LIN_protocol = "2.1";
    configured_NAD = 0x02;
    initial_NAD = 0x02;
    product_id = 0x0076, 0x0000, 0x00;
    response_error = RsErr_FRVC2;
    P2_min = 50 ms;
    ST_min = 0 ms;
    N_As_timeout = 1000 ms;
    N_Cr_timeout = 1000 ms;
    configurable_frames {
      FRVC2_Rq;
      FRVC2_Cval;
    }
  }
  FRVC21 {
    LIN_protocol = "2.1";
    configured_NAD = 0x06;
    initial_NAD = 0x06;
    product_id = 0x0076, 0x0000, 0x00;
    response_error = RsErr_FRVC21;
    P2_min = 50 ms;
    ST_min = 0 ms;
    N_As_timeout = 1000 ms;
    N_Cr_timeout = 1000 ms;
    configurable_frames {
      FRVC21_Rq;
      FRVC21_Cval;
    }
  }
  FRVC25 {
    LIN_protocol = "2.1";
    configured_NAD = 0x13;
    initial_NAD = 0x13;
    product_id = 0x0076, 0x0000, 0x00;
    response_error = RsErr_FRVC25;
    P2_min = 50 ms;
    ST_min = 0 ms;
    N_As_timeout = 1000 ms;
    N_Cr_timeout = 1000 ms;
    configurable_frames {
      FRVC25_Cval;
      FRVC25_Rq;
    }
  }
  FRVC26 {
    LIN_protocol = "2.1";
    configured_NAD = 0x08;
    initial_NAD = 0x08;
    product_id = 0x0076, 0x0000, 0x00;
    response_error = RsErr_FRVC26;
    P2_min = 50 ms;
    ST_min = 0 ms;
    N_As_timeout = 1000 ms;
    N_Cr_timeout = 1000 ms;
    configurable_frames {
      FRVC26_Cval;
      FRVC26_Rq;
    }
  }
  FRVC3 {
    LIN_protocol = "2.1";
    configured_NAD = 0x03;
    initial_NAD = 0x03;
    product_id = 0x0076, 0x0000, 0x00;
    response_error = RsErr_FRVC3;
    P2_min = 50 ms;
    ST_min = 0 ms;
    N_As_timeout = 1000 ms;
    N_Cr_timeout = 1000 ms;
    configurable_frames {
      FRVC3_Rq;
      FRVC3_Cval;
    }
  }
  FRVC4 {
    LIN_protocol = "2.1";
    configured_NAD = 0x04;
    initial_NAD = 0x04;
    product_id = 0x0076, 0x0000, 0x00;
    response_error = RsErr_FRVC4;
    P2_min = 50 ms;
    ST_min = 0 ms;
    N_As_timeout = 1000 ms;
    N_Cr_timeout = 1000 ms;
    configurable_frames {
      FRVC4_Rq;
      FRVC4_Cval;
    }
  }
  P_T_SENSOR {
    LIN_protocol = "2.1";
    configured_NAD = 0x20;
    initial_NAD = 0x20;
    product_id = 0x010D, 0x0001, 0x00;
    response_error = RsErr_P_T_SENSOR2;
    P2_min = 50 ms;
    ST_min = 0 ms;
    configurable_frames {
      P_T_SENS2_Frm;
    }
  }
}

Schedule_tables {
  Init {
    MasterReq	delay	10.000 ms;
    SlaveResp	delay	10.000 ms;
  }
  sch_mreq {
    MasterReq	delay	10.000 ms;
  }
  sch_normal_Batt {
    CPH_BATT1_Rq	delay	10.000 ms;
    CPH_BATT1_C01	delay	10.000 ms;
    CPH_BATT1_C02	delay	10.000 ms;
    FRVC2_Rq	delay	10.000 ms;
    FRVC2_Cval	delay	10.000 ms;
    FRVC3_Rq	delay	10.000 ms;
    FRVC3_Cval	delay	10.000 ms;
    FRVC4_Rq	delay	10.000 ms;
    FRVC4_Cval	delay	10.000 ms;
    ERC2_Rq	delay	10.000 ms;
    DIAG_Stat_ERC2_Frm1	delay	10.000 ms;
    ERC2_Frm1	delay	10.000 ms;
    ERC2_Frm2	delay	10.000 ms;
    HVAC_EXV2_Rq_Frm	delay	10.000 ms;
    EXV2_Frm	delay	10.000 ms;
    P_T_SENS2_Frm	delay	10.000 ms;
    FRVC21_Rq	delay	10.000 ms;
    FRVC21_Cval	delay	10.000 ms;
    FRVC10_Rq	delay	10.000 ms;
    FRVC10_Cval	delay	10.000 ms;
    FRVC19_Rq	delay	10.000 ms;
    FRVC19_Cval	delay	10.000 ms;
    FRVC25_Rq	delay	10.000 ms;
    FRVC25_Cval	delay	10.000 ms;
    FRVC26_Rq	delay	10.000 ms;
    FRVC26_Cval	delay	10.000 ms;
    CABP2_Rq	delay	10.000 ms;
    CABP2_Cval	delay	10.000 ms;
  }
  sch_sresp {
    SlaveResp	delay	10.000 ms;
  }
}

Signal_encoding_types {
  c01_ActPosn_Save {
    logical_value, 0, "POSN_SAVE";
    logical_value, 1, "POSN_NSAVE";
  }
  c01_NACT_ACT {
    logical_value, 0, "NACT";
    logical_value, 1, "ACT";
  }
  c01_NoErr_Err {
    logical_value, 0, "NOERR";
    logical_value, 1, "ERR";
  }
  c01_NotActv_Actv {
    logical_value, 0, "NACT";
    logical_value, 1, "ACTV";
  }
  c02_AKS_Rq {
    logical_value, 0, "ASC_OFF";
    logical_value, 1, "ASC_LOW";
    logical_value, 2, "ASC_HIGH";
    logical_value, 3, "SNA";
  }
  c02_Comp_Rq {
    logical_value, 0, "COMP_OFF";
    logical_value, 1, "COMP_ON";
    logical_value, 2, "NDEF2";
    logical_value, 3, "SNA";
  }
  c02_CptProtn_Stat {
    logical_value, 0, "NORM";
    logical_value, 1, "OVERHEATPREV";
    logical_value, 2, "TPC";
    logical_value, 3, "PWRDERATE";
  }
  c02_Disable_Enable {
    logical_value, 0, "DSBL";
    logical_value, 1, "ENBL";
    logical_value, 2, "RES";
    logical_value, 3, "SNA";
  }
  c02_EXV_InitDir_SNA {
    logical_value, 0, "NO_SELECT";
    logical_value, 1, "LOW_ENDSTOP";
    logical_value, 2, "HIGH_ENDSTOP";
    logical_value, 3, "SNA";
  }
  c02_EXV_InitStat_SNA {
    logical_value, 0, "NO_INIT";
    logical_value, 1, "INIT_IN_PROCESS";
    logical_value, 2, "INIT_READY";
    logical_value, 3, "SNA";
  }
  c02_EXV_Run_Stat {
    logical_value, 0, "NO_MOVEMENT";
    logical_value, 1, "ACT_MOVING";
    logical_value, 2, "NDEF2";
    logical_value, 3, "SNA";
  }
  c02_EXV_Stall_Dtct {
    logical_value, 0, "NO_STALL_DTCT";
    logical_value, 1, "STALL_DTCT_ENBL";
    logical_value, 2, "NDEF2";
    logical_value, 3, "SNA";
  }
  c02_EXV_TempWarn_Stat {
    logical_value, 0, "OK";
    logical_value, 1, "WARN";
    logical_value, 2, "NDEF2";
    logical_value, 3, "SNA";
  }
  c02_EXV_VoltRange {
    logical_value, 0, "VOLT_RNG_OK";
    logical_value, 1, "OVERVOLTAGE";
    logical_value, 2, "UNDERVOLTAGE";
    logical_value, 3, "SNA";
  }
  c02_HVOutOfRngWarn_Stat {
    logical_value, 0, "NACT";
    logical_value, 1, "HVUNDR";
    logical_value, 2, "HVOVR";
    logical_value, 3, "SNA";
  }
  c02_HV_PTC_Reset_Rq {
    logical_value, 0, "NO_RESET";
    logical_value, 1, "RESET";
    logical_value, 2, "NDEF2";
    logical_value, 3, "SNA";
  }
  c02_Inact_Act_Res {
    logical_value, 0, "INACTIVE";
    logical_value, 1, "ACTIVE";
    logical_value, 2, "RES";
    logical_value, 3, "SNA";
  }
  c02_LVOutOfRngWarn_Stat {
    logical_value, 0, "NACT";
    logical_value, 1, "LVUNDR";
    logical_value, 2, "LVOVR";
    logical_value, 3, "SNA";
  }
  c02_Low_High_Ndef_SNA {
    logical_value, 0, "LOW";
    logical_value, 1, "HIGH";
    logical_value, 2, "NDEF";
    logical_value, 3, "SNA";
  }
  c02_MonitActiv {
    logical_value, 0, "MON_ACTIVE";
    logical_value, 1, "NO_MON";
    logical_value, 2, "NDEF";
    logical_value, 3, "SNA";
  }
  c02_NACT_ACT_RES {
    logical_value, 0, "NACT";
    logical_value, 1, "ACT";
    logical_value, 2, "RES";
    logical_value, 3, "SNA";
  }
  c02_Noerror_Error_Ndef {
    logical_value, 0, "NO_ERROR";
    logical_value, 1, "ERROR";
    logical_value, 2, "NDEF";
    logical_value, 3, "SNA";
  }
  c02_Open_Closed_Err_SNA {
    logical_value, 0, "OPEN";
    logical_value, 1, "CLOSED";
    logical_value, 2, "ERR";
    logical_value, 3, "SNA";
  }
  c02_OverHeatWarn_Stat {
    logical_value, 0, "NACT";
    logical_value, 1, "OVERHEATRC";
    logical_value, 2, "OVERHEATCOOL";
    logical_value, 3, "OVERHEATPCB";
  }
  c02_RefRun_Enbl {
    logical_value, 0, "REFRUN_NALW";
    logical_value, 1, "REFRUN_ALW";
    logical_value, 2, "REFRUN_ALW2";
    logical_value, 3, "SNA";
  }
  c02_WakeUp_Stat {
    logical_value, 0, "NO_WUP";
    logical_value, 1, "ACTIVE_WUP";
    logical_value, 2, "NDEF2";
    logical_value, 3, "SNA";
  }
  c02_WakeupStat {
    logical_value, 0, "NO_WUP";
    logical_value, 1, "ACTIVE_WUP";
    logical_value, 2, "NDEF2";
    logical_value, 3, "SNA";
  }
  c03_Comp_Stat {
    logical_value, 0, "COMP_OFF";
    logical_value, 1, "COMP_ON";
    logical_value, 2, "COMP_DEG";
    logical_value, 3, "COMP_STOPP";
    logical_value, 4, "COMP_SHUTDOWN";
    logical_value, 5, "COMP_ASC";
    logical_value, 6, "COMP_NO_RESET";
    logical_value, 7, "SNA";
  }
  c03_EXV_Init_Sequence {
    logical_value, 0, "NO_RQ";
    logical_value, 1, "START_INIT_SQC";
    logical_value, 2, "WAIT_SQC_FINISH";
    logical_value, 3, "LAST_SQC_OK";
    logical_value, 4, "NDEF4";
    logical_value, 5, "NDEF5";
    logical_value, 6, "NDEF6";
    logical_value, 7, "SNA";
  }
  c03_EXV_SpdMode {
    logical_value, 0, "NDEF0";
    logical_value, 1, "SPD_MD_NORM";
    logical_value, 2, "SPD_MD_2";
    logical_value, 3, "SPD_MD_3";
    logical_value, 4, "SPD_MD_HI";
    logical_value, 5, "NDEF5";
    logical_value, 6, "NDEF6";
    logical_value, 7, "SNA";
  }
  c03_EXV_Version {
    logical_value, 0, "VERSION_A";
    logical_value, 1, "VERSION_B";
    logical_value, 2, "VERSION_C";
    logical_value, 3, "VERSION_D";
    logical_value, 4, "VERSION_E";
    logical_value, 5, "VERSION_F";
    logical_value, 6, "VERSION_G";
    logical_value, 7, "SNA";
  }
  c03_HVAC_EXV_Trq_Md_Rq {
    logical_value, 0, "NO_TRQ_CTRL";
    logical_value, 1, "TRQ_20_PRC_LOWER";
    logical_value, 2, "TRQ_10_PRC_LOWER";
    logical_value, 3, "TRQ_NORM";
    logical_value, 4, "TRQ_10_PRC_BOOST";
    logical_value, 5, "TRQ_20_PRC_BOOST";
    logical_value, 6, "RES";
    logical_value, 7, "SNA";
  }
  c03_PostRunMode_SNA {
    logical_value, 0, "NO_POST_RUN";
    logical_value, 1, "SPEED_1";
    logical_value, 2, "SPEED_2";
    logical_value, 3, "SPEED_3";
    logical_value, 4, "SPEED_4";
    logical_value, 5, "NDEF1";
    logical_value, 6, "NDEF2";
    logical_value, 7, "SNA";
  }
  c04_0_to_15_1_SNA_na {
    physical_value, 0, 15, 1, 0, "NoUnit";
  }
  c04_CoolantValve_Move_Stat {
    logical_value, 0, "IDLE";
    logical_value, 1, "CW";
    logical_value, 2, "CCW";
    logical_value, 3, "REF";
    logical_value, 14, "ERR";
    logical_value, 15, "SNA";
  }
  c04_Dischrg_Stat {
    logical_value, 0, "NACT";
    logical_value, 1, "BUSY";
    logical_value, 2, "COMPLETE";
    logical_value, 3, "INCOMPLETE";
    logical_value, 14, "ERR";
    logical_value, 15, "SNA";
  }
  c04_EXV_Flt_Stat_SNA {
    logical_value, 0, "NO_FLT";
    logical_value, 1, "COIL_SHRT";
    logical_value, 2, "COIL_OPN";
    logical_value, 3, "OVR_TMP_SHUTDWN";
    logical_value, 4, "BLOCK";
    logical_value, 5, "STAT_INDET";
    logical_value, 15, "SNA";
  }
  c04_PreHeat_Stat {
    logical_value, 0, "OFF";
    logical_value, 1, "TEMPLOCK";
    logical_value, 2, "OVERHEATLOCK";
    logical_value, 3, "PERMLOCK";
    logical_value, 4, "OPER";
    logical_value, 5, "PRODMD";
    logical_value, 6, "POSTPRODMD";
    logical_value, 7, "ACTDISCHRG";
    logical_value, 14, "ERR";
    logical_value, 15, "SNA";
  }
  c04_TJA_Posn {
    logical_value, 0, "OPEN";
    logical_value, 1, "STEP_1";
    logical_value, 2, "STEP_2";
    logical_value, 3, "STEP_3";
    logical_value, 4, "STEP_4";
    logical_value, 5, "STEP_5";
    logical_value, 6, "STEP_6";
    logical_value, 7, "STEP_7";
    logical_value, 8, "STEP_8";
    logical_value, 9, "CLOSE";
    logical_value, 10, "RES1";
    logical_value, 11, "RES2";
    logical_value, 12, "RES3";
    logical_value, 13, "RES4";
    logical_value, 14, "ERR";
    logical_value, 15, "SNA";
  }
  c04_noErr_OpnErr_ClsErr {
    logical_value, 0, "NOERR";
    logical_value, 1, "OPNERR";
    logical_value, 2, "CLSERR";
    logical_value, 3, "NOMOVE";
    logical_value, 4, "RES";
    logical_value, 5, "RES2";
    logical_value, 6, "RES3";
    logical_value, 7, "RES4";
    logical_value, 8, "RES5";
    logical_value, 9, "RES6";
    logical_value, 10, "RES7";
    logical_value, 11, "RES8";
    logical_value, 12, "RES9";
    logical_value, 13, "RES10";
    logical_value, 14, "ERR";
    logical_value, 15, "SNA";
  }
  c06_0_to_63_1_SNA_na {
    physical_value, 0, 63, 1, 0, "NoUnit";
  }
  c07_A_0_126_1 {
    physical_value, 0, 126, 1, 0, "A_PC";
    logical_value, 127, "SNA";
  }
  c08_A_0_50k8_0k2_SNA {
    physical_value, 0, 254, 0.2, 0, "A_PC";
    logical_value, 255, "SNA";
  }
  c08_A_0_to_62d5_0d25 {
    physical_value, 0, 250, 0.25, 0, "A";
    logical_value, 254, "ERR";
    logical_value, 255, "SNA";
  }
  c08_HV_PTC_HV_DC_curr {
    physical_value, 0, 254, 0.25, 0, "A";
    logical_value, 255, "SNA";
  }
  c08_V_0_1016_4 {
    physical_value, 0, 254, 4, 0, "V";
    logical_value, 255, "SNA";
  }
  c08_V_0_25k4_0k1_cv {
    physical_value, 0, 254, 0.1, 0, "V";
    logical_value, 255, "SNA";
  }
  c08_degC_m50_204_1 {
    physical_value, 0, 254, 1, -50, "°C_PC";
    logical_value, 255, "SNA";
  }
  c08_degCels_m50_to_204_1_SNA_na {
    physical_value, 0, 254, 1, -50, "°C";
    logical_value, 255, "SNA";
  }
  c08_degCelsius_m50_to_170_1 {
    physical_value, 0, 220, 1, -50, "°C";
    logical_value, 254, "ERR";
    logical_value, 255, "SNA";
  }
  c08_kW_0_to_20d32_0d08 {
    physical_value, 0, 254, 0.08, 0, "kW";
    logical_value, 255, "SNA";
  }
  c08_perc_0_101k6_0k4_SNA {
    physical_value, 0, 254, 0.4, 0, "%_PC";
    logical_value, 255, "SNA";
  }
  c08_percent_0_to_100_0k5_ERR {
    physical_value, 0, 200, 0.5, 0, "%";
    logical_value, 254, "ERR";
    logical_value, 255, "SNA";
  }
  c10_0_1022 {
    physical_value, 0, 1022, 1, 0, "NoUnit";
    logical_value, 1023, "SNA";
  }
  c12_bar_0_36k0184_0k0088 {
    physical_value, 0, 4093, 0.0088, 0, "bar";
    logical_value, 4094, "RES";
    logical_value, 4095, "SNA";
  }
  c12_degC_m40_150_0k1 {
    physical_value, 0, 1900, 0.1, -40, "°C";
    logical_value, 4095, "SNA";
  }
  c16_Steps_0_to_65533_1 {
    physical_value, 0, 65533, 1, 0, "Steps";
    logical_value, 65534, "ERR";
    logical_value, 65535, "SNA";
  }
  c16_V_0_to_3212k75_0k05 {
    physical_value, 0, 64255, 0.05, 0, "V";
    logical_value, 65535, "SNA";
  }
}

Signal_representation {
  c01_ActPosn_Save : ActPosnSave_Rq_TIO_FRVC10, ActPosnSave_Rq_TIO_FRVC19, ActPosnSave_Rq_TIO_FRVC2, ActPosnSave_Rq_TIO_FRVC21, ActPosnSave_Rq_TIO_FRVC25, ActPosnSave_Rq_TIO_FRVC26, ActPosnSave_Rq_TIO_FRVC3, ActPosnSave_Rq_TIO_FRVC4;
  c01_NACT_ACT : AllPosnAdj_Stat_FRVC10, AllPosnAdj_Stat_FRVC19, AllPosnAdj_Stat_FRVC2, AllPosnAdj_Stat_FRVC21, AllPosnAdj_Stat_FRVC25, AllPosnAdj_Stat_FRVC26, AllPosnAdj_Stat_FRVC3, AllPosnAdj_Stat_FRVC4, EltlErr_Stat_FRVC10, EltlErr_Stat_FRVC19, EltlErr_Stat_FRVC2, EltlErr_Stat_FRVC21, EltlErr_Stat_FRVC25, EltlErr_Stat_FRVC26, EltlErr_Stat_FRVC3, EltlErr_Stat_FRVC4, GrpErr_Stat_FRVC10, GrpErr_Stat_FRVC19, GrpErr_Stat_FRVC2, GrpErr_Stat_FRVC21, GrpErr_Stat_FRVC25, GrpErr_Stat_FRVC26, GrpErr_Stat_FRVC3, GrpErr_Stat_FRVC4, MechBreakErr_Stat_FRVC10, MechBreakErr_Stat_FRVC19, MechBreakErr_Stat_FRVC2, MechBreakErr_Stat_FRVC21, MechBreakErr_Stat_FRVC25, MechBreakErr_Stat_FRVC26, MechBreakErr_Stat_FRVC3, MechBreakErr_Stat_FRVC4, OverTempErr_Stat_FRVC10, OverTempErr_Stat_FRVC19, OverTempErr_Stat_FRVC2, OverTempErr_Stat_FRVC21, OverTempErr_Stat_FRVC25, OverTempErr_Stat_FRVC26, OverTempErr_Stat_FRVC3, OverTempErr_Stat_FRVC4, OverTempWarn_Stat_FRVC10, OverTempWarn_Stat_FRVC19, OverTempWarn_Stat_FRVC2, OverTempWarn_Stat_FRVC21, OverTempWarn_Stat_FRVC25, OverTempWarn_Stat_FRVC26, OverTempWarn_Stat_FRVC3, OverTempWarn_Stat_FRVC4, OverVoltErr_Stat_FRVC10, OverVoltErr_Stat_FRVC19, OverVoltErr_Stat_FRVC2, OverVoltErr_Stat_FRVC21, OverVoltErr_Stat_FRVC25, OverVoltErr_Stat_FRVC26, OverVoltErr_Stat_FRVC3, OverVoltErr_Stat_FRVC4, PosSnaErr_Stat_FRVC10, PosSnaErr_Stat_FRVC19, PosSnaErr_Stat_FRVC2, PosSnaErr_Stat_FRVC21, PosSnaErr_Stat_FRVC25, PosSnaErr_Stat_FRVC26, PosSnaErr_Stat_FRVC3, PosSnaErr_Stat_FRVC4, RefRunErr_Stat_FRVC10, RefRunErr_Stat_FRVC19, RefRunErr_Stat_FRVC2, RefRunErr_Stat_FRVC21, RefRunErr_Stat_FRVC25, RefRunErr_Stat_FRVC26, RefRunErr_Stat_FRVC3, RefRunErr_Stat_FRVC4, RefRun_Stat_FRVC10, RefRun_Stat_FRVC19, RefRun_Stat_FRVC2, RefRun_Stat_FRVC21, RefRun_Stat_FRVC25, RefRun_Stat_FRVC26, RefRun_Stat_FRVC3, RefRun_Stat_FRVC4, UndrVoltErr_Stat_FRVC10, UndrVoltErr_Stat_FRVC19, UndrVoltErr_Stat_FRVC2, UndrVoltErr_Stat_FRVC21, UndrVoltErr_Stat_FRVC25, UndrVoltErr_Stat_FRVC26, UndrVoltErr_Stat_FRVC3, UndrVoltErr_Stat_FRVC4, UnexpBlkErr_Stat_FRVC10, UnexpBlkErr_Stat_FRVC19, UnexpBlkErr_Stat_FRVC2, UnexpBlkErr_Stat_FRVC21, UnexpBlkErr_Stat_FRVC25, UnexpBlkErr_Stat_FRVC26, UnexpBlkErr_Stat_FRVC3, UnexpBlkErr_Stat_FRVC4;
  c01_NoErr_Err : RsErr_Cval_CABP2, RsErr_Stat_CPH_BATT1;
  c01_NotActv_Actv : Dischrg_Rq_TIO_CPH_BATT1, HtEnbl_Rq_TIO_CPH_BATT1;
  c02_AKS_Rq : ASC_TIO_ERC2;
  c02_Comp_Rq : CmprOn_Rq_TIO_ERC2;
  c02_CptProtn_Stat : CptProtn_Stat_CPH_BATT1;
  c02_Disable_Enable : HVAC_EXV2_Move_Enbl;
  c02_EXV_InitDir_SNA : HVAC_EXV2_Init_Dir;
  c02_EXV_InitStat_SNA : EXV2_curInit_Stat;
  c02_EXV_Run_Stat : EXV2_Run_Stat;
  c02_EXV_Stall_Dtct : EXV2_Stall_Dtct_Stat, HVAC_EXV2_Stall_Dtct_Enbl;
  c02_EXV_TempWarn_Stat : EXV2_OverTemp_Warn;
  c02_EXV_VoltRange : EXV2_Volt_Stat;
  c02_HVOutOfRngWarn_Stat : HVOutOfRngWarn_Stat_CPH_BATT1;
  c02_HV_PTC_Reset_Rq : Rst_Rq_TIO_ERC2;
  c02_Inact_Act_Res : SemiConductSwRq_TIO_CPH_BATT1, SemiConductSwRq_TIO_ERC2;
  c02_LVOutOfRngWarn_Stat : LVOutOfRngWarn_Stat_CPH_BATT1;
  c02_Low_High_Ndef_SNA : PWM_Stat_CABP2;
  c02_MonitActiv : Mon_Stat_CABP2;
  c02_NACT_ACT_RES : DCDCCnvrFai_Stat_CPH_BATT1, HiCurrFai_Stat_CPH_BATT1, HotSptFai_Stat_CPH_BATT1, IGBTDrvFai_Stat_CPH_BATT1, IntFai_Stat_CPH_BATT1, TempSensFai_Stat_CPH_BATT1;
  c02_Noerror_Error_Ndef : BlockFlt_Stat_CABP2, DryRun_Flt_Stat_CABP2, ElctrcFlt_Stat_CABP2, OverCurrFlt_Stat_CABP2, OverTempFlt_Stat_CABP2, SpVoltFlt_Stat_CABP2;
  c02_Open_Closed_Err_SNA : SemiConductSw_Stat_CPH_BATT1, SemiConductSw_Stat_ERC2;
  c02_OverHeatWarn_Stat : OverHeatWarn_Stat_CPH_BATT1;
  c02_RefRun_Enbl : RefRunEnbl_Rq_TIO_FRVC10, RefRunEnbl_Rq_TIO_FRVC19, RefRunEnbl_Rq_TIO_FRVC2, RefRunEnbl_Rq_TIO_FRVC21, RefRunEnbl_Rq_TIO_FRVC25, RefRunEnbl_Rq_TIO_FRVC26, RefRunEnbl_Rq_TIO_FRVC3, RefRunEnbl_Rq_TIO_FRVC4;
  c02_WakeUp_Stat : WakeupStat_EXV2, Wakeup_Stat_ERC2;
  c02_WakeupStat : WakeUp_Stat_FRVC10, WakeUp_Stat_FRVC19, WakeUp_Stat_FRVC2, WakeUp_Stat_FRVC21, WakeUp_Stat_FRVC25, WakeUp_Stat_FRVC26, WakeUp_Stat_FRVC3, WakeUp_Stat_FRVC4, Wakeup_Stat_CABP2;
  c03_Comp_Stat : CmprOprtnV2_Stat_ERC2;
  c03_EXV_Init_Sequence : HVAC_EXV2_Init_Rq;
  c03_EXV_SpdMode : EXV2_SpdMd, HVAC_EXV2_SpdMd_Rq;
  c03_EXV_Version : EXV2_Version;
  c03_HVAC_EXV_Trq_Md_Rq : HVAC_EXV2_Trq_Md_Rq;
  c03_PostRunMode_SNA : PostRunMode_CABP2;
  c04_0_to_15_1_SNA_na : DIAG_Stat_Aliv_St_Cnt_ERC2;
  c04_CoolantValve_Move_Stat : Move_Stat_FRVC10, Move_Stat_FRVC19, Move_Stat_FRVC2, Move_Stat_FRVC21, Move_Stat_FRVC25, Move_Stat_FRVC26, Move_Stat_FRVC3, Move_Stat_FRVC4;
  c04_Dischrg_Stat : Dischrg_Stat_CPH_BATT1;
  c04_EXV_Flt_Stat_SNA : EXV2_Fault_Stat;
  c04_PreHeat_Stat : CoolntPreHt_Stat_CPH_BATT1;
  c04_TJA_Posn : StepPosn_Stat_FRVC10, StepPosn_Stat_FRVC19, StepPosn_Stat_FRVC2, StepPosn_Stat_FRVC21, StepPosn_Stat_FRVC25, StepPosn_Stat_FRVC26, StepPosn_Stat_FRVC3, StepPosn_Stat_FRVC4;
  c04_noErr_OpnErr_ClsErr : Err_Stat_FRVC10, Err_Stat_FRVC19, Err_Stat_FRVC2, Err_Stat_FRVC21, Err_Stat_FRVC25, Err_Stat_FRVC26, Err_Stat_FRVC3, Err_Stat_FRVC4;
  c06_0_to_63_1_SNA_na : DIAG_Stat_Data1_ERC2, DIAG_Stat_Data2_ERC2, DIAG_Stat_Data3_ERC2, DIAG_Stat_Data4_ERC2, DIAG_Stat_Data5_ERC2, DIAG_Stat_Data6_ERC2, DIAG_Stat_Data7_ERC2, DIAG_Stat_Data8_ERC2, DIAG_Stat_Idx_Actl_ERC2, DIAG_Stat_Num_Max_ERC2;
  c07_A_0_126_1 : HV_PhaseCurr_Cval_ERC2;
  c08_A_0_50k8_0k2_SNA : ActlCurr_Cval_CABP2;
  c08_A_0_to_62d5_0d25 : HVCurr_Cval_CPH_BATT1;
  c08_HV_PTC_HV_DC_curr : HV_DCCurr_Cval_ERC2;
  c08_V_0_1016_4 : HV_Volt_Cval_ERC2;
  c08_V_0_25k4_0k1_cv : LoVolt_Cval_CABP2;
  c08_degC_m50_204_1 : InvTemp_Cval_ERC2;
  c08_degCels_m50_to_204_1_SNA_na : ElctrcTemp_Cval_CABP2;
  c08_degCelsius_m50_to_170_1 : CoolntInTemp_Cval_CPH_BATT1, CoolntOutTemp_Cval_CPH_BATT1, CoolntTemp_Rq_TIO_CPH_BATT1;
  c08_kW_0_to_20d32_0d08 : PowerCons_Cval_ERC2;
  c08_perc_0_101k6_0k4_SNA : PerctSpd_Cval_CABP2, TrgtPerctSpd_Cval_CABP2, TrgtPerctSpd_Rq_CABP2;
  c08_percent_0_to_100_0k5_ERR : CmprSpdTrgtV2_Rq_TIO_ERC2, CmprSpdV2_Cval_ERC2, Perct_Cval_CPH_BATT1, Perct_Rq_TIO_CPH_BATT1;
  c10_0_1022 : EXV2_Pos, HVAC_EXV2_Set_Rq;
  c12_bar_0_36k0184_0k0088 : P_T_Sens2_CoolPress;
  c12_degC_m40_150_0k1 : P_T_Sens2_CoolTemp, P_T_Sens2_IntTemp;
  c16_Steps_0_to_65533_1 : InfVarPosn_Cval_FRVC10, InfVarPosn_Cval_FRVC19, InfVarPosn_Cval_FRVC2, InfVarPosn_Cval_FRVC21, InfVarPosn_Cval_FRVC25, InfVarPosn_Cval_FRVC26, InfVarPosn_Cval_FRVC3, InfVarPosn_Cval_FRVC4, InfVarPosn_Rq_TIO_FRVC10, InfVarPosn_Rq_TIO_FRVC19, InfVarPosn_Rq_TIO_FRVC2, InfVarPosn_Rq_TIO_FRVC21, InfVarPosn_Rq_TIO_FRVC25, InfVarPosn_Rq_TIO_FRVC26, InfVarPosn_Rq_TIO_FRVC3, InfVarPosn_Rq_TIO_FRVC4;
  c16_V_0_to_3212k75_0k05 : HVVolt_Cval_CPH_BATT1;
}
